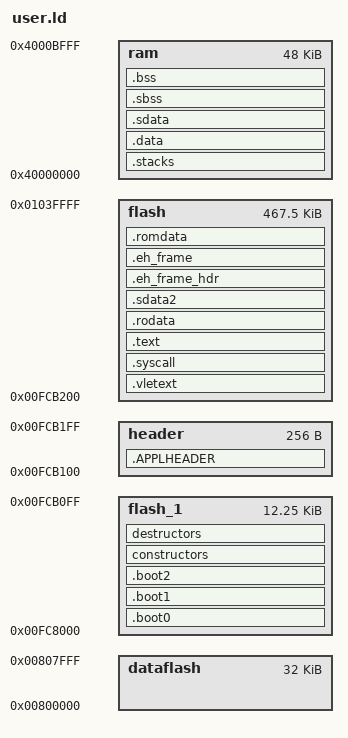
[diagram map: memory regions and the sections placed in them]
/*
    SPC5 RLA - Copyright (C) 2015 STMicroelectronics

    Licensed under the Apache License, Version 2.0 (the "License").
    You may not use this file except in compliance with the License.
    You may obtain a copy of the License at

        http://www.apache.org/licenses/LICENSE-2.0

    Unless required by applicable law or agreed to in writing, software
    distributed under the License is distributed on an "AS IS" BASIS,
    WITHOUT WARRANTIES OR CONDITIONS OF ANY KIND, either express or implied.
    See the License for the specific language governing permissions and
    limitations under the License.
*/

/*
 * This file is automatically generated and can be overwritten, do no change
 * this file manually.
 */

/*
 * SPC570Sxx memory setup.
 */

DEFAULTS {
__irq_stack_size__      = 0
__process_stack_size__  = 2048
}

MEMORY
{
    flash_1   : org = 0x00FC8000, len = 0x00FCb100 - 0x00FC8000
	header    : org = 0x00FCb100, len = 0x100
	flash     : org = 0x00FCb200, len = 0x01040000 - 0x00FCb200
    dataflash : org = 0x00800000, len = 32k
    ram       : org = 0x40000000, len = 48k
}

OPTION ("-e=_reset_address")

SECTIONS
{
    . = ADDR(flash);
    .boot0 ALIGN(16) :
    {
        *(.boot)
        . = ALIGN(16); 
        *(.handlers)
        . = ALIGN(16); 
        *(.crt0)
    } > flash_1

    .boot1 align (0x1000):
    {
        /* The vectors table requires a 4kB alignment.*/
        *(.vectors)
    } > flash_1

    .boot2 align (0x1000):
    {
        __ivpr_base__ = .;
        /* The IVPR register requires a 4kB alignment.*/
        *(.ivors)
    } > flash_1

    constructors  ALIGN(4) :
    {
        __init_array_start = .;
        "*(.init_array.*)"   
        *(.init_array)
        __init_array_end = .;
    } > flash_1

    destructors  ALIGN(4) :
    {
        __fini_array_start = .;
        *(.fini_array)
        "*(.fini_array.*)"   
        __fini_array_end = .;
    } > flash_1
	
	.APPLHEADER :
    {
        *(.APPLHEADER)        
    } > header
	
    .vletext  ALIGN(16)  :
    {
        *(.vletext)
        "*(.vletext.*)"
        "*(.ghs.linkonce.t_vle.*)"
        *(.text_vle)
        "*(.text_vle.*)"
        "*(.gnu.linkonce.t_vle.*)"
    } > flash

    .syscall ALIGN(16) :
    {
        *(.syscall)
        "*(.syscall.*)"
        "*(.ghs.linkonce.t_vle.*)"
    } > flash

    .text  ALIGN(16)  :
    {
        *(.text)
        "*(.text.*)"
        "*(.ghs.linkonce.t.*)"
    } > flash

    .rodata  ALIGN(16) :
    {
        *(.rodata)
        "*(.rodata.*)"
    } > flash

    .sdata2  ALIGN(16) :
    {
        __sdata2_start__ = . + 0x8000;
        *(.sdata2)
        "*(.sdata2.*)"
        "*(.ghs.linkonce.s2.*)"
        *(.sbss2)
        "*(.sbss2.*)"
        "*(.ghs.linkonce.sb2.*)"
    } > flash

    .eh_frame_hdr :
    {
        *(.eh_frame_hdr)
    } > flash

    .eh_frame : 
    {
        *(.eh_frame)
    } > flash

    .romdata  ALIGN(16) :
    {
        __romdata_start__ = .;
    } > flash

    .stacks ALIGN(16) :
    {
        . = ALIGN(8);
        __irq_stack_base__ = .;
        . += __irq_stack_size__;
        . = ALIGN(8);
        __irq_stack_end__ = .;
        __process_stack_base__ = .;
        __main_thread_stack_base__ = .;
        . += __process_stack_size__;
        . = ALIGN(8);
        __process_stack_end__ = .;
        __main_thread_stack_end__ = .;
    } > ram

    .data : AT(__romdata_start__)
    {
        . = ALIGN(4);
        __data_start__ = .;
        *(.data)
        "*(.data.*)"
        "*(.ghs.linkonce.d.*)"
    } > ram

    .sdata :
    {
        . = ALIGN(4);
        __sdata_start__ = . + 0x8000;
        *(.sdata)
        "*(.sdata.*)"
        "*(.ghs.linkonce.s.*)"
        __data_end__ = .;
    } > ram

    .sbss :
    {
        __bss_start__ = .;
        *(.sbss)
        "*(.sbss.*)"
        "*(.ghs.linkonce.sb.*)"
        *(.scommon)
    } > ram

    .bss :
    {
        *(.bss)
        "*(.bss.*)"
        "*(.ghs.linkonce.b.*)"
        *(COMMON)
        __bss_end__ = .;
    } > ram

    __flash_size__      = sizeof(flash);
    __flash_start__     = addr(flash);
    __flash_end__       = endaddr(flash);
    __ram_size__        = sizeof(ram);
    __ram_start__       = addr(ram);
    __ram_end__         = endaddr(ram);
    __dataflash_size__  = sizeof(dataflash);
    __dataflash_start__ = addr(dataflash);
	__dataflash_end__   = endaddr(dataflash);
    __heap_base__       = __bss_end__;
    __heap_end__        = __ram_end__;
	__ghsend_heap		= __heap_end__;
	__ghsbegin_heap		= __heap_base__;
}
